AUTOSAR XML (schema 4-4-0)
package /ComponentTypes
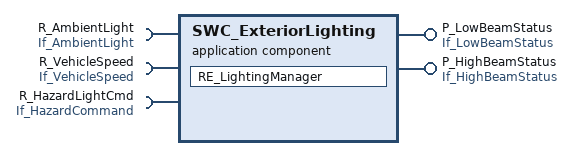
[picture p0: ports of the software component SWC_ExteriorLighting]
  application sw component type SWC_ExteriorLighting: category=APPLICATION_SWC
    require port R_AmbientLight: required-interface=If_AmbientLight
    require port R_VehicleSpeed: required-interface=If_VehicleSpeed
    provide port P_LowBeamStatus: provided-interface=If_LowBeamStatus
    provide port P_HighBeamStatus: provided-interface=If_HighBeamStatus
    require port R_HazardLightCmd: required-interface=If_HazardCommand
    behavior IB_ExteriorLighting
      runnable RE_LightingManager
        data-read-access:
          access DRA_AmbientLight: accessed-variable=R_AmbientLight.LightLevelLux
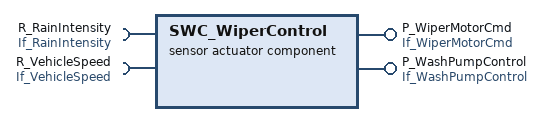
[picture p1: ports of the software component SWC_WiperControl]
  sensor actuator sw component type SWC_WiperControl: category=SENSOR_ACTUATOR_SWC
    require port R_RainIntensity: required-interface=If_RainIntensity
    require port R_VehicleSpeed: required-interface=If_VehicleSpeed
    provide port P_WiperMotorCmd: provided-interface=If_WiperMotorCmd
    provide port P_WashPumpControl: provided-interface=If_WashPumpControl
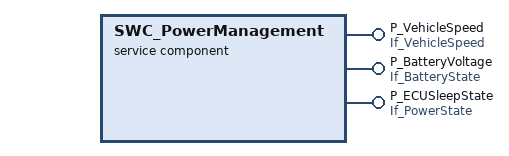
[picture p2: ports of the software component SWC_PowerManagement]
  service sw component type SWC_PowerManagement
    provide port P_VehicleSpeed: provided-interface=If_VehicleSpeed
    provide port P_BatteryVoltage: provided-interface=If_BatteryState
    provide port P_ECUSleepState: provided-interface=If_PowerState
package /Interfaces
  sender receiver interface If_VehicleSpeed
    data SpeedKmh: type=uint16
  sender receiver interface If_AmbientLight
    data LightLevelLux: type=uint16
  sender receiver interface If_HazardCommand
    data HazardActive: type=boolean
